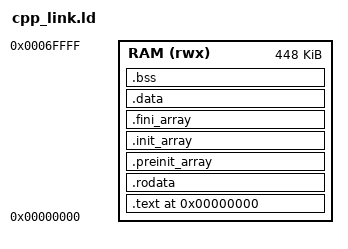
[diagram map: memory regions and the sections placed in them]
OUTPUT_ARCH(riscv)
ENTRY(_start)

MEMORY
{
    RAM (rwx) : ORIGIN = 0x00000000, LENGTH = 0x00070000
}

PROVIDE(__stack_top = ORIGIN(RAM) + LENGTH(RAM) - 0x1000);

SECTIONS
{
    . = ORIGIN(RAM);

    .text : ALIGN(4)
    {
        KEEP(*(.text.start))
        *(.init)
        *(.text .text.*)
        *(.gnu.linkonce.t.*)
    } > RAM

    .rodata : ALIGN(4)
    {
        *(.rodata .rodata.*)
        *(.srodata .srodata.*)
        *(.gnu.linkonce.r.*)
    } > RAM

    .preinit_array : ALIGN(4)
    {
        PROVIDE_HIDDEN(__preinit_array_start = .);
        KEEP(*(.preinit_array))
        PROVIDE_HIDDEN(__preinit_array_end = .);
    } > RAM

    .init_array : ALIGN(4)
    {
        PROVIDE_HIDDEN(__init_array_start = .);
        KEEP(*(SORT_BY_INIT_PRIORITY(.init_array.*) SORT_BY_INIT_PRIORITY(.ctors.*)))
        KEEP(*(.init_array .ctors))
        PROVIDE_HIDDEN(__init_array_end = .);
    } > RAM

    .fini_array : ALIGN(4)
    {
        PROVIDE_HIDDEN(__fini_array_start = .);
        KEEP(*(SORT_BY_INIT_PRIORITY(.fini_array.*) SORT_BY_INIT_PRIORITY(.dtors.*)))
        KEEP(*(.fini_array .dtors))
        PROVIDE_HIDDEN(__fini_array_end = .);
    } > RAM

    .data : ALIGN(4)
    {
        PROVIDE(__global_pointer$ = . + 0x800);
        __data_start = .;
        *(.sdata .sdata.*)
        *(.data .data.*)
        *(.gnu.linkonce.d.*)
        __data_end = .;
    } > RAM
    __data_load_start = LOADADDR(.data);

    .bss (NOLOAD) : ALIGN(4)
    {
        __bss_start = .;
        *(.sbss .sbss.*)
        *(.bss .bss.*)
        *(COMMON)
        __bss_end = .;
    } > RAM

    . = ALIGN(16);
    __heap_start = .;
    __heap_end = __stack_top;

    /DISCARD/ :
    {
        *(.comment)
        *(.riscv.attributes)
        *(.eh_frame)
        *(.eh_frame_hdr)
    }
}
